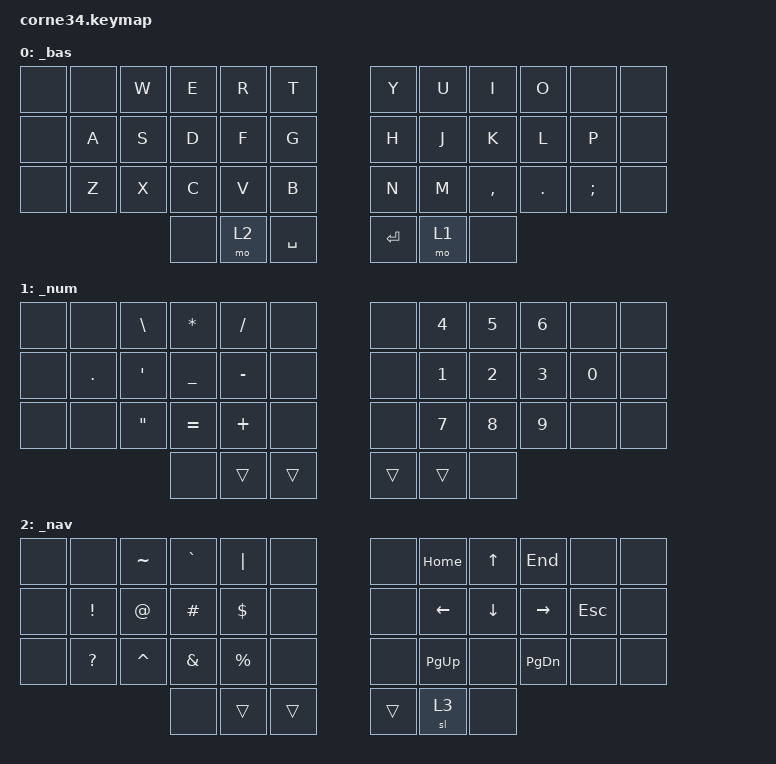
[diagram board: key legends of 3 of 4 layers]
#include <behaviors.dtsi>
#include <dt-bindings/zmk/keys.h>

/ {
    combos {
        compatible = "zmk,combos";

        cb_tab {
            bindings = <&kp TAB>;
            key-positions = <2 3>;
        };

        cb_del {
            bindings = <&kp DEL>;
            key-positions = <38 39>;
        };

        cb_cntl {
            bindings = <&sk LCTRL>;
            key-positions = <26 27>;
        };

        cb_gui {
            bindings = <&sk LGUI>;
            key-positions = <38 37>;
        };

        cb_alt {
            bindings = <&sk RALT>;
            key-positions = <40 39>;
        };

        cb_bkspc {
            bindings = <&kp BSPC>;
            key-positions = <9 8>;
        };

        cb_lbkt {
            bindings = <&kp LBKT>;
            layers = <0 1>;
            key-positions = <2 14>;
        };

        cb_lpara {
            bindings = <&kp LPAR>;
            layers = <0 1>;
            key-positions = <3 15>;
        };

        cb_lbrc {
            bindings = <&kp LBRC>;
            layers = <0 1>;
            key-positions = <4 16>;
        };

        cb_rbkt {
            bindings = <&kp RBRC>;
            layers = <0 1>;
            key-positions = <7 19>;
        };

        cb_rpara {
            bindings = <&kp RPAR>;
            layers = <0 1>;
            key-positions = <8 20>;
        };

        cb_rbrc {
            bindings = <&kp RBKT>;
            layers = <0 1>;
            key-positions = <9 21>;
        };

        cb_q {
            bindings = <&kp Q>;
            layers = <0>;
            key-positions = <13 22>;
        };
    };

    keymap {
        compatible = "zmk,keymap";

        _bas {
            bindings = <
  //────────────┬─────────────┬─────────────┬─────────────┬─────────────╮ ╭──╮ ╭─────────────┬─────────────┬─────────────┬─────────────┬─────────────╮
  &none &none         &kp W         &kp E        &kp R         &kp T            &kp Y         &kp U         &kp I         &kp O         &none    &none      
  &none &kp A         &kp S         &kp D        &kp F         &kp G            &kp H         &kp J         &kp K         &kp L         &kp P    &none      
  &none &kp Z         &kp X         &kp C        &kp V         &kp B            &kp N         &kp M         &kp COMMA     &kp DOT       &kp SEMI &none  
  //────────────┴─────────────┴─────────────┼─────────────┼─────────────┤ ├──┤ ├─────────────┼─────────────┼─────────────┴─────────────┴─────────────╯    
  &none                                        &mo 2         &kp SPACE          &kp ENTER     &mo 1         &none 
  //                                        ╰─────────────┴─────────────╯ ╰──╯ ╰─────────────┴─────────────╯
            >;
        };

        _num {
            bindings = <
  //────────────┬─────────────┬─────────────┬─────────────┬─────────────╮ ╭──╮ ╭─────────────┬─────────────┬─────────────┬─────────────┬─────────────╮        
  &none &none         &kp BSLH      &kp STAR     &kp FSLH      &none            &none         &kp N4        &kp N5        &kp N6        &none     &none         
  &none &kp DOT       &kp SQT       &kp UNDER    &kp MINUS     &none            &none         &kp N1        &kp N2        &kp N3        &kp N0    &none       
  &none &none         &kp DQT       &kp EQUAL    &kp PLUS      &none            &none         &kp N7        &kp N8        &kp N9        &none     &none 
  //────────────┴─────────────┴─────────────┼─────────────┼─────────────┤ ├──┤ ├─────────────┼─────────────┼─────────────┴─────────────┴─────────────╯          
  &none                                        &trans        &trans             &trans        &trans        &none  
  //                                        ╰─────────────┴─────────────╯ ╰──╯ ╰─────────────┴─────────────╯ 
            >;
        };

        _nav {
            bindings = <
  //────────────┬─────────────┬─────────────┬─────────────┬─────────────╮ ╭──╮ ╭─────────────┬─────────────┬─────────────┬─────────────┬─────────────╮
  &none &none         &kp TILDE     &kp GRAVE    &kp PIPE      &none            &none         &kp HOME      &kp UP        &kp END       &none     &none    
  &none &kp EXCL      &kp AT        &kp POUND    &kp DLLR      &none            &none         &kp LEFT      &kp DOWN      &kp RIGHT     &kp ESC   &none    
  &none &kp QMARK     &kp CARET     &kp AMPS     &kp PRCNT     &none            &none         &kp PG_UP     &none         &kp PG_DN     &none     &none 
  //────────────┴─────────────┴─────────────┼─────────────┼─────────────┤ ├──┤ ├─────────────┼─────────────┼─────────────┴─────────────┴─────────────╯   
  &none                                        &trans        &trans             &trans        &sl 3         &none   
  //                                        ╰─────────────┴─────────────╯ ╰──╯ ╰─────────────┴─────────────╯ 
            >;
        };

        _fun {
            bindings = <
  //────────────┬─────────────┬─────────────┬─────────────┬─────────────╮ ╭──╮ ╭─────────────┬─────────────┬─────────────┬─────────────┬─────────────╮
  &none         &none         &none        &none         &none               &none         &kp F4        &kp F5        &kp F6        &none        
  &none         &none         &none        &none         &none               &kp F11       &kp F1        &kp F2        &kp F3        &kp F10      
  &none         &none         &none        &none         &none               &kp F12       &kp F7        &kp F8        &kp F9        &none   
  //────────────┴─────────────┴─────────────┼─────────────┼─────────────┤ ├──┤ ├─────────────┼─────────────┼─────────────┴─────────────┴─────────────╯      
  &none                                       &trans        &trans              &trans        &trans        &none   
  //                                        ╰─────────────┴─────────────╯ ╰──╯ ╰─────────────┴─────────────╯      
             >;
        };
    };
};
